# APM32L07x register map
File version: 1.0
CPU: CM0+ r0p0, little endian, MPU, no FPU, 4 interrupt priority bits
Registers are 32-bit, read-write, reset 0x0 unless marked. A register's access mark holds for its fields unless they carry their own. Offsets are from the block's base; [hi:lo] are bit positions; {n}, {i} and the like mark numbered series.

## SYSCFG — System configuration controller
Base 0x40010000
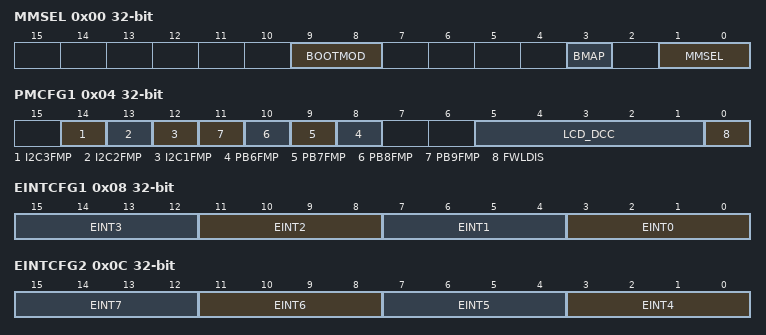
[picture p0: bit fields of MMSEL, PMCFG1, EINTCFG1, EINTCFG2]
0x00 MMSEL access per field — memory remap register
  [9:8] BOOTMOD ro — BOOT Mode
  [3] BMAP rw — Bank Map
  [1:0] MMSEL rw — Memory mapping selection bits
0x04 PMCFG1 — peripheral mode configuration register
  [14] I2C3FMP — FM+ Driving Capability Activate for I2C3 Pins
  [13] I2C2FMP — FM+ Driving Capability Activate for I2C2 Pins
  [12] I2C1FMP — FM+ Driving Capability Activate for I2C1 Pins
  [n+2] PB{n}FMP (n=6..9) — Fast Mode Plus Driving Capability Activate for PB{n}
  [5:1] LCD_DCC — LCD Decoupling Capacitance Connection
  [0] FWLDIS — Firewall Disable
0x08 EINTCFG1 — external interrupt configuration register 1
  [4n+3:4n] EINT{n} (n=0..3) — EINT {n} configuration bits
0x0C EINTCFG2 — external interrupt configuration register 2
  [4n-13:4n-16] EINT{n} (n=4..7) — EINT {n} configuration bits
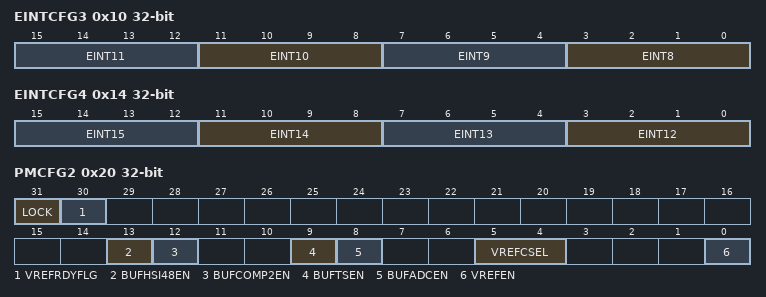
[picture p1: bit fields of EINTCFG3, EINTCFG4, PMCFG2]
0x10 EINTCFG3 — external interrupt configuration register 3
  [4n-29:4n-32] EINT{n} (n=8..11) — EINT {n} configuration bits
0x14 EINTCFG4 — external interrupt configuration register 4
  [4n-45:4n-48] EINT{n} (n=12..15) — EINT {n} configuration bits
0x20 PMCFG2 — peripheral mode configuration register
  [31] LOCK
  [30] VREFRDYFLG ro — VREFINT Ready Flag
  [13] BUFHSI48EN — Buffer for HSICLK48 Enable
  [12] BUFCOMP2EN — Buffer for COMP2 Enable
  [9] BUFTSEN — Buffer for Temperature Sensor Enable
  [8] BUFADCEN — Buffer for ADC Enable
  [5:4] VREFCSEL — Pin Connect ADC VREFINT Select
  [0] VREFEN — VREFINT Enable

## TMR6 — Basic-timers
Base 0x40001000
Same registers: TMR7 0x40001400
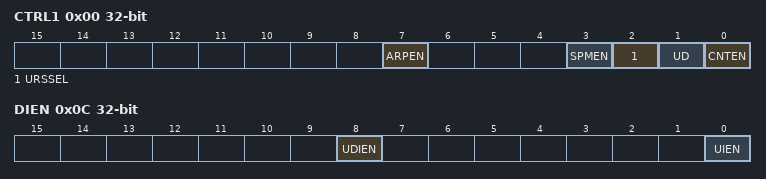
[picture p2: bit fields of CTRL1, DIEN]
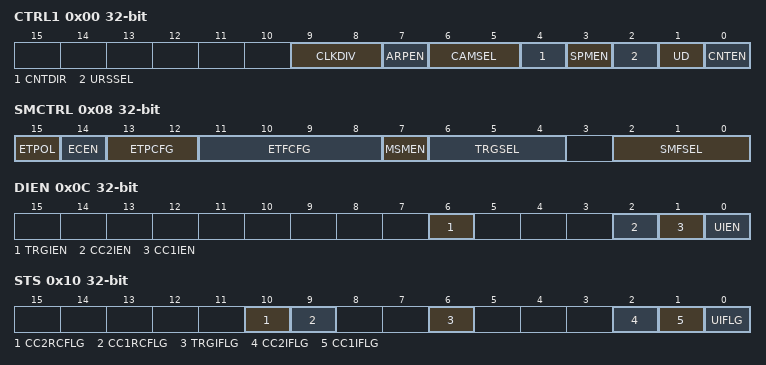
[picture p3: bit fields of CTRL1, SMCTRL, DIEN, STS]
0x00 CTRL1 — control register 1
  [7] ARPEN — Auto-reload preload enable
  [3] SPMEN — One-pulse mode
  [2] URSSEL — Update request source
  [1] UD — Update disable
  [0] CNTEN — Counter enable
0x04 CTRL2 — control register 2
  [6:4] MMSEL — Master mode selection
0x0C DIEN — DMA/Interrupt enable register
  [8] UDIEN — Update DMA request enable
  [0] UIEN — Update interrupt enable
0x10 STS — status register
  [0] UIFLG — Update interrupt flag
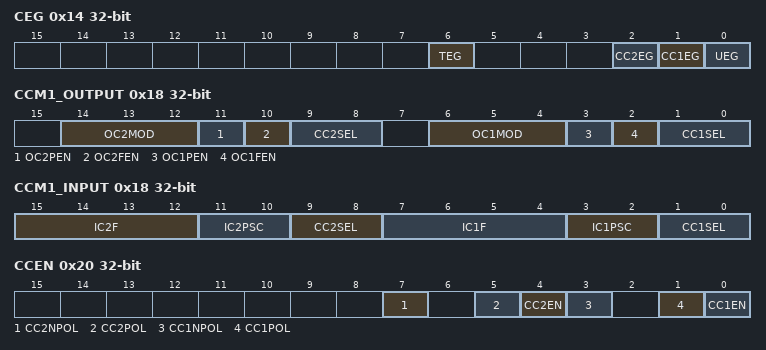
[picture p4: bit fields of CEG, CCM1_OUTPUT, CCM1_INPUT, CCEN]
0x14 CEG wo — event generation register
  [0] UEG — Update generation
0x24 CNT — counter
  [15:0] CNT — Counter value
0x28 PSC — prescaler
  [15:0] PSC — Prescaler value
0x2C AUTORLD reset 0xFFFF — auto-reload register
  [15:0] AUTORLD — Auto-reload value

## TMR21 — General-purpose-timers
Base 0x40010800
Same registers: TMR22 0x40014400
0x00 CTRL1 — control register 1
  [9:8] CLKDIV — Clock division
  [7] ARPEN — Auto-reload preload enable
  [6:5] CAMSEL — Center Aligned Mode Select
  [4] CNTDIR — Counter Direction
  [3] SPMEN — One-pulse mode
  [2] URSSEL — Update request source
  [1] UD — Update disable
  [0] CNTEN — Counter enable
0x04 CTRL2 — control register 2
  [6:4] MMSEL — Master mode selection
0x08 SMCTRL — slave mode control register
  [15] ETPOL — External Trigger Polarity Configure
  [14] ECEN — External Clock Enable Mode2
  [13:12] ETPCFG — External Trigger Prescaler Configure
  [11:8] ETFCFG — External Trigger Filter Configure
  [7] MSMEN — Master/Slave mode
  [6:4] TRGSEL — Trigger selection
  [2:0] SMFSEL — Slave mode selection
0x0C DIEN — DMA/Interrupt enable register
  [6] TRGIEN — Trigger interrupt enable
  [2] CC2IEN — Capture/Compare 2 interrupt enable
  [1] CC1IEN — Capture/Compare 1 interrupt enable
  [0] UIEN — Update interrupt enable
0x10 STS — status register
  [10] CC2RCFLG — Capture/compare 2 overcapture flag
  [9] CC1RCFLG — Capture/Compare 1 overcapture flag
  [6] TRGIFLG — Trigger interrupt flag
  [2] CC2IFLG — Capture/Compare 2 interrupt flag
  [1] CC1IFLG — Capture/compare 1 interrupt flag
  [0] UIFLG — Update interrupt flag
0x14 CEG wo — event generation register
  [6] TEG — Trigger generation
  [2] CC2EG — Capture/compare 2 generation
  [1] CC1EG — Capture/compare 1 generation
  [0] UEG — Update generation
0x18 CCM1_OUTPUT — capture/compare mode register (output mode)
  [14:12] OC2MOD — Output Compare 2 mode
  [11] OC2PEN — Output Compare 2 preload enable
  [10] OC2FEN — Output Compare 2 fast enable
  [9:8] CC2SEL — Capture/Compare 2 selection
  [6:4] OC1MOD — Output Compare 1 mode
  [3] OC1PEN — Output Compare 1 preload enable
  [2] OC1FEN — Output Compare 1 fast enable
  [1:0] CC1SEL — Capture/Compare 1 selection
0x18 CCM1_INPUT (alternate view of CCM1_OUTPUT) — capture/compare mode register 1 (input mode)
  [15:12] IC2F — Input capture 2 filter
  [11:10] IC2PSC — Input capture 2 prescaler
  [9:8] CC2SEL — Capture/Compare 2 selection
  [7:4] IC1F — Input capture 1 filter
  [3:2] IC1PSC — Input capture 1 prescaler
  [1:0] CC1SEL — Capture/Compare 1 selection
0x20 CCEN — capture/compare enable register
  [7] CC2NPOL — Capture/Compare 2 output Polarity
  [5] CC2POL — Capture/Compare 2 output Polarity
  [4] CC2EN — Capture/Compare 2 output enable
  [3] CC1NPOL — Capture/Compare 1 output Polarity
  [1] CC1POL — Capture/Compare 1 output Polarity
  [0] CC1EN — Capture/Compare 1 output enable
0x24 CNT — counter
  [15:0] CNT — Counter value
0x28 PSC — prescaler
  [15:0] PSC — Prescaler value
0x2C AUTORLD reset 0xFFFF — auto-reload register
  [15:0] AUTORLD — Auto-reload value
0x34 CC1 — capture/compare register 1
  [15:0] CC1 — Capture/Compare 1 value
0x38 CC2 — capture/compare register 2
  [15:0] CC2 — Capture/Compare 2 value
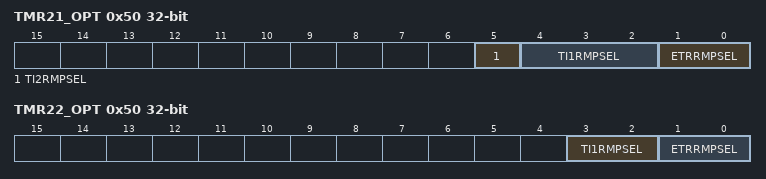
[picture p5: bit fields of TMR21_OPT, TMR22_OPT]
0x50 TMR21_OPT — TMR21 option register
  [5] TI2RMPSEL — TI2 Connected to TMR21_CH1 Remap
  [4:2] TI1RMPSEL — TI1 Connected to TMR21_CH1 Remap
  [1:0] ETRRMPSEL — Timer21 ETR Remap Select
0x50 TMR22_OPT (alternate view of TMR21_OPT) — TMR22 option register
  [3:2] TI1RMPSEL — TI1 Connected to TMR22_CH1 Remap
  [1:0] ETRRMPSEL — Timer22 ETR Remap Select
